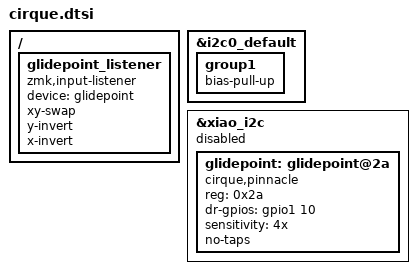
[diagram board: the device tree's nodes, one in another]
#include <dt-bindings/zmk/mouse.h>
#include <behaviors/mouse_keys.dtsi>

&i2c0_default {
    group1 {
      bias-pull-up;
    };
};

&xiao_i2c {
    status = "disabled";                           
    glidepoint: glidepoint@2a {
        compatible = "cirque,pinnacle";
        reg = <0x2a>;
        status = "okay";
        dr-gpios = <&gpio1 10 (GPIO_ACTIVE_HIGH)>;

        sensitivity = "4x";
        // sleep;
        no-taps;
    };
};

/ {
  glidepoint_listener {
    compatible = "zmk,input-listener";
    device = <&glidepoint>;

    xy-swap;
    y-invert;
    x-invert;
  };
};
